# STM32U5F9 register map
File version: 1.3
CPU: CM33 r0p1, little endian, MPU, FPU, 4 interrupt priority bits
Registers are 32-bit, read-write, reset 0x0 unless marked. A register's access mark holds for its fields unless they carry their own. Offsets are from the block's base; [hi:lo] are bit positions; {n}, {i} and the like mark numbered series.

## TIM15 — General purpose timers
Base 0x40014000
Same registers: SEC_TIM15 0x50014000
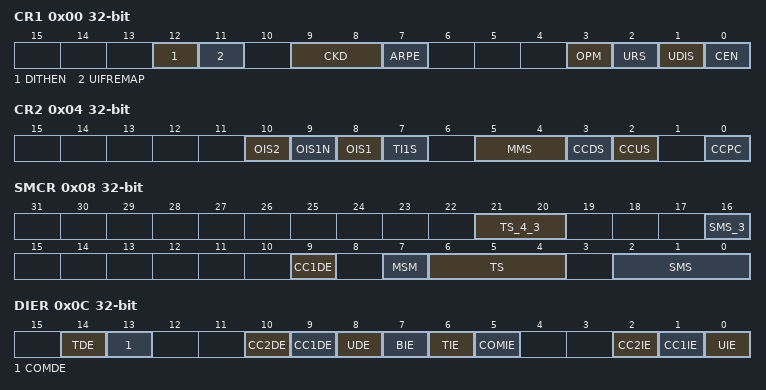
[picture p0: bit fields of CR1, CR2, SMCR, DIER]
0x00 CR1 — control register 1
  [12] DITHEN — Dithering enable
  [11] UIFREMAP — UIF status bit remapping
  [9:8] CKD — Clock division
  [7] ARPE — Auto-reload preload enable
  [3] OPM — One-pulse mode
  [2] URS — Update request source
  [1] UDIS — Update disable
  [0] CEN — Counter enable
0x04 CR2 — control register 2
  [10] OIS2 — Output idle state 2 (OC2
  [9] OIS1N — Output Idle state 1
  [8] OIS1 — Output Idle state 1
  [7] TI1S — TI1 selection
  [5:4] MMS — Master mode selection
  [3] CCDS — Capture/compare DMA
  [2] CCUS — Capture/compare control update
  [0] CCPC — Capture/compare preloaded
0x08 SMCR — slave mode control register
  [21:20] TS_4_3 — Trigger selection
    {v}=Internal Trigger {v} (tim_itr{v}) (v=0..3)
  [16] SMS_3 — Slave mode selection
    0=Slave mode disabled - if CEN = 1' then the prescaler is clocked directly by the internal clock; 1=Quadrature encoder mode 1, x2 mode- Counter counts up/down on tim_ti1fp1 edge depending on tim_ti2fp2 level
  [9] CC1DE — Capture/Compare 1 DMA request
  [7] MSM — Master/slave mode
  [6:4] TS — Trigger selection
    {v}=Internal Trigger {v} (tim_itr{v}) (v=0..3); 4=tim_ti1 Edge Detector (tim_ti1f_ed); 5=Filtered Timer Input 1 (tim_ti1fp1); 6=Filtered Timer Input 2 (tim_ti2fp2); 7=External Trigger input (tim_etrf)
  [2:0] SMS — Slave mode selection
    0=Slave mode disabled - if CEN = 1' then the prescaler is clocked directly by the internal clock; 1=Quadrature encoder mode 1, x2 mode- Counter counts up/down on tim_ti1fp1 edge depending on tim_ti2fp2 level; 2=Quadrature encoder mode 2, x2 mode - Counter counts up/down on tim_ti2fp2 edge depending on tim_ti1fp1 level; 3=Quadrature encoder mode 3, x4 mode - Counter counts up/down on both tim_ti1fp1 and tim_ti2fp2 edges depending on the level of the other input; 4=Reset Mode - Rising edge of the selected trigger input (tim_trgi) reinitializes the counter and generates an update of the registers; 5=Gated Mode - The counter clock is enabled when the trigger input (tim_trgi) is high; 6=Trigger Mode - The counter starts at a rising edge of the trigger tim_trgi (but it is not reset); 7=External Clock Mode 1 - Rising edges of the selected trigger (tim_trgi) clock the counter
0x0C DIER — DMA/Interrupt enable register
  [14] TDE — Trigger DMA request enable
  [13] COMDE — COM DMA request enable
  [10] CC2DE — Capture/Compare 2 DMA request
  [9] CC1DE — Capture/Compare 1 DMA request
  [8] UDE — Update DMA request enable
  [7] BIE — Break interrupt enable
  [6] TIE — Trigger interrupt enable
  [5] COMIE — COM interrupt enable
  [2] CC2IE — Capture/Compare 2 interrupt
  [1] CC1IE — Capture/Compare 1 interrupt
  [0] UIE — Update interrupt enable
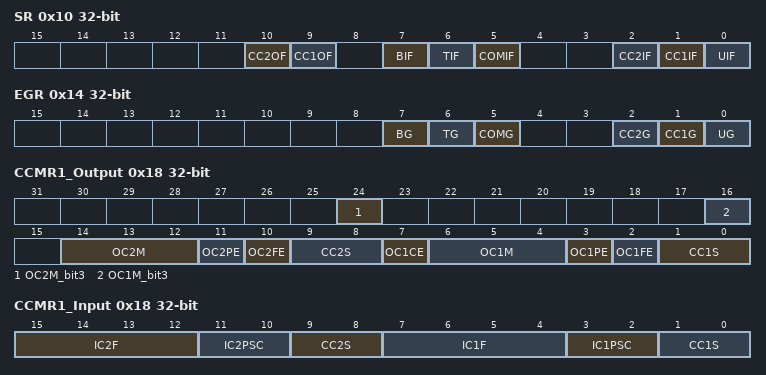
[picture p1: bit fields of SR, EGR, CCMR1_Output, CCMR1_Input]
0x10 SR — status register
  [10] CC2OF — Capture/Compare 2 overcapture
  [9] CC1OF — Capture/Compare 1 overcapture
  [7] BIF — Break interrupt flag
  [6] TIF — Trigger interrupt flag
  [5] COMIF — COM interrupt flag
  [2] CC2IF — Capture/Compare 2 interrupt
  [1] CC1IF — Capture/compare 1 interrupt
  [0] UIF — Update interrupt flag
0x14 EGR access per field — event generation register
  [7] BG wo — Break generation
  [6] TG wo — Trigger generation
  [5] COMG rw — Capture/Compare control update
  [2] CC2G wo — Capture/Compare 2
  [1] CC1G wo — Capture/compare 1
  [0] UG wo — Update generation
0x18 CCMR1_Output — capture/compare mode register (output
  [24] OC2M_bit3 — Output Compare 2 mode - bit
  [16] OC1M_bit3 — Output Compare 1 mode
  [14:12] OC2M — Output Compare 2 mode
  [11] OC2PE — Output Compare 2 preload
  [10] OC2FE — Output compare 2 fast enable
  [9:8] CC2S — Capture/Compare 2
  [7] OC1CE — Output compare 1 clear enable
  [6:4] OC1M — Output Compare 1 mode
  [3] OC1PE — Output Compare 1 preload
  [2] OC1FE — Output Compare 1 fast
  [1:0] CC1S — Capture/Compare 1
0x18 CCMR1_Input (alternate view of CCMR1_Output) — capture/compare mode register 1 (input
  [15:12] IC2F — Input capture 2 filter
  [11:10] IC2PSC — Input capture 2 prescaler
  [9:8] CC2S — Capture/Compare 2
  [7:4] IC1F — Input capture 1 filter
  [3:2] IC1PSC — Input capture 1 prescaler
  [1:0] CC1S — Capture/Compare 1
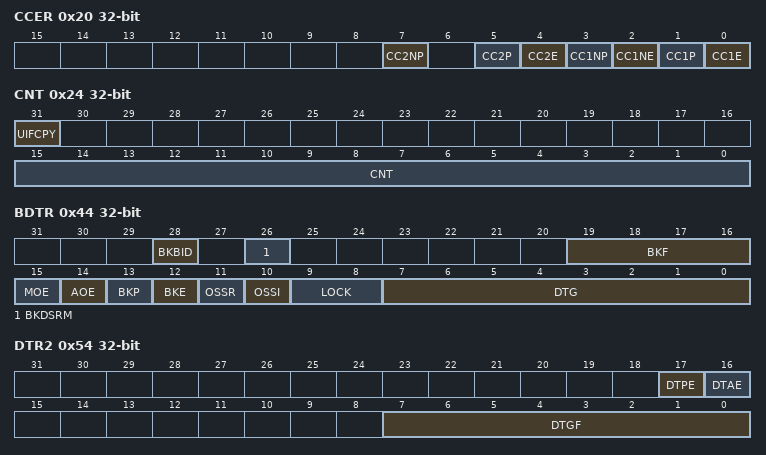
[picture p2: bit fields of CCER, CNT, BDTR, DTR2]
0x20 CCER — capture/compare enable
  [7] CC2NP — Capture/Compare 2 complementary output
  [5] CC2P — Capture/Compare 2 output
  [4] CC2E — Capture/Compare 2 output
  [3] CC1NP — Capture/Compare 1 output
  [2] CC1NE — Capture/Compare 1 complementary output
  [1] CC1P — Capture/Compare 1 output
  [0] CC1E — Capture/Compare 1 output
0x24 CNT access per field — counter
  [31] UIFCPY ro — UIF Copy
  [15:0] CNT rw — counter value
0x28 PSC — prescaler
  [15:0] PSC — Prescaler value
0x2C ARR reset 0xFFFF — auto-reload register
  [19:0] ARR — Auto-reload value
0x30 RCR — repetition counter register
  [7:0] REP — Repetition counter value
0x34 CCR1 — capture/compare register 1
  [19:0] CCR1 — Capture/Compare 1 value
0x38 CCR2 — capture/compare register 2
  [19:0] CCR2 — Capture/Compare 2 value
0x44 BDTR — break and dead-time register
  [28] BKBID — Break Bidirectional
  [26] BKDSRM — Break Disarm
  [19:16] BKF — Break filter
  [15] MOE — Main output enable
  [14] AOE — Automatic output enable
  [13] BKP — Break polarity
  [12] BKE — Break enable
  [11] OSSR — Off-state selection for Run
  [10] OSSI — Off-state selection for Idle
  [9:8] LOCK — Lock configuration
  [7:0] DTG — Dead-time generator setup
0x54 DTR2 — timer deadtime register 2
  [17] DTPE — Deadtime preload enable
  [16] DTAE — Deadtime asymmetric enable
  [7:0] DTGF — Dead-time falling edge generator setup
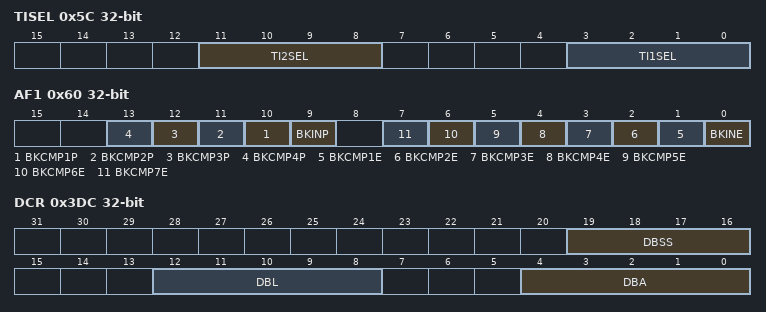
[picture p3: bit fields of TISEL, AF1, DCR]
0x5C TISEL — input selection register
  [11:8] TI2SEL — selects tim_ti2_in[0..15] input
  [3:0] TI1SEL — selects tim_ti1_in[0..15] input
0x60 AF1 — alternate function register 1
  [n+9] BKCMP{n}P (n=1..4) — tim_brk_cmp{n} input polarity
  [9] BKINP — TIMx_BKIN input polarity
  [n] BKCMP{n}E (n=1..7) — tim_brk_cmp{n} enable
  [0] BKINE — TIMx_BKIN input enable
0x64 AF2 reset 0x1 — alternate function register 2
  [18:16] OCRSEL — ocref_clr source selection
0x3DC DCR — DMA control register
  [19:16] DBSS — DMA burst source selection
  [12:8] DBL — DMA burst length
  [4:0] DBA — DMA base address
0x3E0 DMAR — DMA address for full transfer
  [31:0] DMAB — DMA register for burst accesses
